# AUX_SPIM register map
Vendor: Texas Instruments
Peripheral module from a debugger description file (folder CC2652).
Registers are 32-bit, read-only, reset 0x0 unless marked. A register's access mark holds for its fields unless they carry their own. Offsets are as the file gives them; lines under a group give offsets from that group; [hi:lo] are bit positions; {n}, {i} and the like mark numbered series; 'fields as' and 'values as' point back to an identical list; <NAME> marks a mode.

## AUX_SPIM — The AUX Serial Peripheral Interface Master (AUX_SPIM) enables AUX_SCE with power-efficient SPI communication. It is not possible to write a register while SPI transmission occurs. An attempt to do so will stall the bus until transmission is complete. Read of RX8.DATA or RX16.DATA stalls the bus until LSB has been captured. Read of SCLKIDLE.STAT or DATAIDLE.STAT stalls the bus until condition described is met. Other read operations do not stall the bus. AUX_SCE becomes clock gated if it encounters a bus stall. This is useful as AUX_SCE can write TX8.DATA and then read RX8.DATA immediately to read a SPI slave. In such case there is no need for software to wait or to poll registers. AUX_SYSIF:PEROPRATE.SPIM_OP_RATE selects the peripheral clock frequency which is used to derive the SCLK frequency. AUX_SCE must set AUX_SYSIF:PEROPRATE.SPIM_OP_RATE to SCE_RATE to access and use AUX_SPIM. System CPU must set AUX_SYSIF:PEROPRATE.SPIM_OP_RATE to BUS_RATE to access and use AUX_SPIM. Failure to do so can result in incorrect SPI transmission.
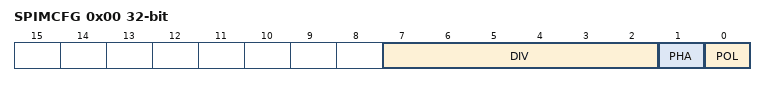
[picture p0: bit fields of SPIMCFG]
0x00 SPIMCFG access per field — SPI Master Configuration Write operation stalls until current transfer completes.
  [7:2] DIV rw — SCLK divider. Peripheral clock frequency division gives the SCLK clock frequency. The division factor equals (2 * (DIV+1)): 0x00: Divide by 2. 0x01: Divide by 4. 0x02: Divide by 6. ... 0x3F: Divide by 128.
  [1] PHA rw — Phase of the MOSI and MISO data signals. 0: Sample MISO at leading (odd) edges and shift MOSI at trailing (even) edges of SCLK. 1: Sample MISO at trailing (even) edges and shift MOSI at leading (odd) edges of SCLK.
  [0] POL rw — Polarity of the SCLK signal. 0: SCLK is low when idle, first clock edge rises. 1: SCLK is high when idle, first clock edge falls.
0x04 MISOCFG access per field — MISO Configuration Write operation stalls until current transfer completes.
  [4:0] AUXIO rw — AUXIO to MISO mux. Select the AUXIO pin that connects to MISO.
0x08 MOSICTL wo — MOSI Control Write operation stalls until current transfer completes.
  [0] VALUE — MOSI level control. 0: Set MOSI low. 1: Set MOSI high.
0x0C TX8 wo — Transmit 8 Bit Write operation stalls until current transfer completes.
  [7:0] DATA — 8 bit data transfer. Write DATA to start transfer, MSB first. When transfer completes, MOSI stays at the value of LSB.
0x10 TX16 wo — Transmit 16 Bit Write operation stalls until current transfer completes.
  [15:0] DATA — 16 bit data transfer. Write DATA to start transfer, MSB first. When transfer completes, MOSI stays at the value of LSB.
0x14 RX8 — Receive 8 Bit Read operation stalls until current transfer completes.
  [7:0] DATA — Latest 8 bits received on MISO.
0x18 RX16 — Receive 16 Bit Read operation stalls until current transfer completes.
  [15:0] DATA — Latest 16 bits received on MISO.
0x1C SCLKIDLE reset 0x1 — SCLK Idle Read operation stalls until SCLK is idle with no remaining clock edges.
  [0] STAT — Wait for SCLK idle. Read operation stalls until SCLK is idle with no remaining clock edges. Read then returns 1. AUX_SCE can use this to control CS deassertion.
0x20 DATAIDLE reset 0x1 — Data Idle Read operation stalls until current transfer completes.
  [0] STAT — Wait for data idle. Read operation stalls until the SCLK period associated with LSB transmission completes. Read then returns 1. AUX_SCE can use this to control CS deassertion.
